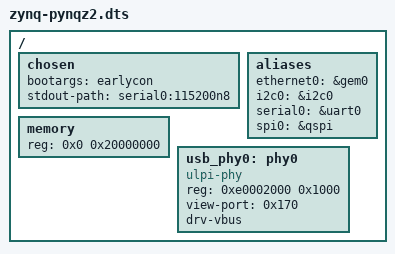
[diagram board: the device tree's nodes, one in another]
/*
 * CAUTION: This file is automatically generated by Xilinx.
 * Version:  
 * Today is: Thu Apr  9 12:48:12 2020
 */


/dts-v1/;
/include/ "zynq-7000.dtsi"
/include/ "pl.dtsi"
/include/ "pcw.dtsi"
/ {
	chosen {
		bootargs = "earlycon";
		stdout-path = "serial0:115200n8";
	};
	aliases {
		ethernet0 = &gem0;
		i2c0 = &i2c0;
		serial0 = &uart0;
		spi0 = &qspi;
	};
	memory {
		device_type = "memory";
		reg = <0x0 0x20000000>;
	};
	usb_phy0: phy0 {
		compatible = "ulpi-phy";
		#phy-cells = <0>;
		reg = <0xe0002000 0x1000>;
		view-port = <0x170>;
		drv-vbus;
	};
};
